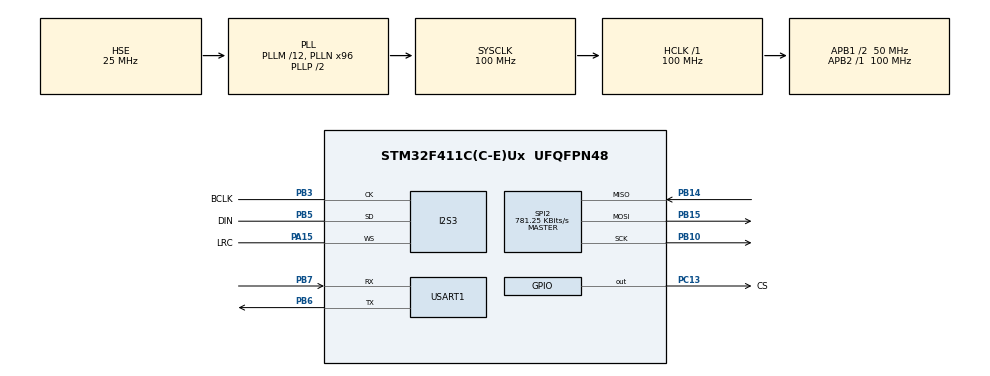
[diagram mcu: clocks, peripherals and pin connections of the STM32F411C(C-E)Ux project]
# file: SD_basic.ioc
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Dma.Request0=SPI2_RX
Dma.Request1=SPI2_TX
Dma.Request2=SPI3_TX
Dma.SPI2_RX.0.Direction=DMA_PERIPH_TO_MEMORY
Dma.SPI2_RX.0.FIFOMode=DMA_FIFOMODE_DISABLE
Dma.SPI2_RX.0.Instance=DMA1_Stream3
Dma.SPI2_RX.0.MemDataAlignment=DMA_MDATAALIGN_BYTE
Dma.SPI2_RX.0.MemInc=DMA_MINC_ENABLE
Dma.SPI2_RX.0.Mode=DMA_NORMAL
Dma.SPI2_RX.0.PeriphDataAlignment=DMA_PDATAALIGN_BYTE
Dma.SPI2_RX.0.PeriphInc=DMA_PINC_DISABLE
Dma.SPI2_RX.0.Priority=DMA_PRIORITY_LOW
Dma.SPI2_TX.1.Direction=DMA_MEMORY_TO_PERIPH
Dma.SPI2_TX.1.FIFOMode=DMA_FIFOMODE_DISABLE
Dma.SPI2_TX.1.Instance=DMA1_Stream4
Dma.SPI2_TX.1.MemDataAlignment=DMA_MDATAALIGN_BYTE
Dma.SPI2_TX.1.MemInc=DMA_MINC_ENABLE
Dma.SPI2_TX.1.Mode=DMA_NORMAL
Dma.SPI2_TX.1.PeriphDataAlignment=DMA_PDATAALIGN_BYTE
Dma.SPI2_TX.1.PeriphInc=DMA_PINC_DISABLE
Dma.SPI2_TX.1.Priority=DMA_PRIORITY_LOW
Dma.SPI3_TX.2.Direction=DMA_MEMORY_TO_PERIPH
Dma.SPI3_TX.2.FIFOMode=DMA_FIFOMODE_DISABLE
Dma.SPI3_TX.2.Instance=DMA1_Stream5
Dma.SPI3_TX.2.MemDataAlignment=DMA_MDATAALIGN_BYTE
Dma.SPI3_TX.2.MemInc=DMA_MINC_ENABLE
Dma.SPI3_TX.2.Mode=DMA_CIRCULAR
Dma.SPI3_TX.2.PeriphDataAlignment=DMA_PDATAALIGN_BYTE
Dma.SPI3_TX.2.PeriphInc=DMA_PINC_DISABLE
Dma.SPI3_TX.2.Priority=DMA_PRIORITY_LOW
FATFS._USE_LABEL=1
FATFS._USE_LFN=3
I2S3.AudioFreq=I2S_AUDIOFREQ_44K
I2S3.ErrorAudioFreq=-0.43 %
I2S3.FullDuplexMode=I2S_FULLDUPLEXMODE_DISABLE
I2S3.Instance=SPI$Index
I2S3.RealAudioFreq=43.808 KHz
I2S3.VirtualMode=I2S_MODE_MASTER
Mcu.Family=STM32F4
Mcu.Name=STM32F411C(C-E)Ux
Mcu.Package=UFQFPN48
NVIC.DMA1_Stream3_IRQn=true\:0\:0\:false\:false\:true\:false\:true\:true
NVIC.DMA1_Stream4_IRQn=true\:0\:0\:false\:false\:true\:false\:true\:true
NVIC.DMA1_Stream5_IRQn=true\:0\:0\:false\:false\:true\:false\:true\:true
NVIC.PriorityGroup=NVIC_PRIORITYGROUP_4
PA13.Mode=Serial_Wire
PA13.Signal=SYS_JTMS-SWDIO
PA14.Mode=Serial_Wire
PA14.Signal=SYS_JTCK-SWCLK
PA15.GPIO_Label=LRC
PA15.Mode=Half_Duplex_Master
PA15.Signal=I2S3_WS
PB10.Mode=Full_Duplex_Master
PB10.Signal=SPI2_SCK
PB14.Mode=Full_Duplex_Master
PB14.Signal=SPI2_MISO
PB15.Mode=Full_Duplex_Master
PB15.Signal=SPI2_MOSI
PB3.GPIO_Label=BCLK
PB3.Mode=Half_Duplex_Master
PB3.Signal=I2S3_CK
PB5.GPIO_Label=DIN
PB5.Mode=Half_Duplex_Master
PB5.Signal=I2S3_SD
PB6.Mode=Asynchronous
PB6.Signal=USART1_TX
PB7.Mode=Asynchronous
PB7.Signal=USART1_RX
PC13-ANTI_TAMP.GPIO_Label=CS
PC13-ANTI_TAMP.GPIO_Speed=GPIO_SPEED_FREQ_HIGH
PC13-ANTI_TAMP.PinState=GPIO_PIN_SET
PC13-ANTI_TAMP.Signal=GPIO_Output
PH0\ -\ OSC_IN.Mode=HSE-External-Oscillator
PH0\ -\ OSC_IN.Signal=RCC_OSC_IN
PH1\ -\ OSC_OUT.Mode=HSE-External-Oscillator
PH1\ -\ OSC_OUT.Signal=RCC_OSC_OUT
ProjectManager.HeapSize=0x200
ProjectManager.StackSize=0x400
ProjectManager.TargetToolchain=STM32CubeIDE
RCC.48MHZClocksFreq_Value=50000000
RCC.AHBFreq_Value=100000000
RCC.APB1CLKDivider=RCC_HCLK_DIV2
RCC.APB1Freq_Value=50000000
RCC.APB1TimFreq_Value=100000000
RCC.APB2Freq_Value=100000000
RCC.APB2TimFreq_Value=100000000
RCC.CortexFreq_Value=100000000
RCC.HCLKFreq_Value=100000000
RCC.HSE_VALUE=25000000
RCC.HSI_VALUE=16000000
RCC.LSE_VALUE=32768
RCC.PLLM=12
RCC.PLLN=96
RCC.PLLSourceVirtual=RCC_PLLSOURCE_HSE
RCC.SYSCLKFreq_VALUE=100000000
RCC.SYSCLKSource=RCC_SYSCLKSOURCE_PLLCLK
RCC.VCOOutputFreq_Value=200000000
SPI2.BaudRatePrescaler=SPI_BAUDRATEPRESCALER_64
SPI2.CalculateBaudRate=781.25 KBits/s
SPI2.Direction=SPI_DIRECTION_2LINES
SPI2.Mode=SPI_MODE_MASTER
SPI2.VirtualType=VM_MASTER
USART1.VirtualMode=VM_ASYNC
VP_FATFS_VS_Generic.Mode=User_defined
board=custom

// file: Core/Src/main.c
/* USER CODE BEGIN Header */
/**
  ******************************************************************************
  * @file           : main.c
  * @brief          : Main program body
  ******************************************************************************
  * @attention
  *
  * Copyright (c) 2026 STMicroelectronics.
  * All rights reserved.
  *
  * This software is licensed under terms that can be found in the LICENSE file
  * in the root directory of this software component.
  * If no LICENSE file comes with this software, it is provided AS-IS.
  *
  ******************************************************************************
  */
/* USER CODE END Header */
#include "main.h"
#include "fatfs.h"

/* USER CODE BEGIN Includes */
#include "sd_functions.h"
#include "stdio.h"
#include "sd_benchmark.h"
#include "wav_player.h"

/* USER CODE END Includes */

I2S_HandleTypeDef hi2s3;
DMA_HandleTypeDef hdma_spi3_tx;

SPI_HandleTypeDef hspi2;
DMA_HandleTypeDef hdma_spi2_rx;
DMA_HandleTypeDef hdma_spi2_tx;

UART_HandleTypeDef huart1;

void SystemClock_Config(void);
static void MX_GPIO_Init(void);
static void MX_DMA_Init(void);
static void MX_USART1_UART_Init(void);
static void MX_SPI2_Init(void);
static void MX_I2S3_Init(void);

/* USER CODE BEGIN 0 */
int _write(int fd, unsigned char *buf, int len) {
  if (fd == 1 || fd == 2) {                     // stdout or stderr ?
    HAL_UART_Transmit(&huart1, buf, len, 999);  // Print to the UART
  }
  return len;
}
/* USER CODE END 0 */

int main(void)
{

  /* MCU Configuration--------------------------------------------------------*/

  /* Reset of all peripherals, Initializes the Flash interface and the Systick. */
  HAL_Init();

  /* Configure the system clock */
  SystemClock_Config();

  /* Initialize all configured peripherals */
  MX_GPIO_Init();
  MX_DMA_Init();
  MX_USART1_UART_Init();
  MX_SPI2_Init();
  MX_I2S3_Init();
  /* USER CODE BEGIN 2 */
  sd_mount();
  sd_list_files();
  wav_set_volume(128);          /* 50% para começar */
  wav_play("bad_romance.wav");
  sd_unmount();
  /* USER CODE END 2 */

  /* Infinite loop */
  while (1)
  {

  }
}

void SystemClock_Config(void)
{
  RCC_OscInitTypeDef RCC_OscInitStruct = {0};
  RCC_ClkInitTypeDef RCC_ClkInitStruct = {0};

  /** Configure the main internal regulator output voltage
  */
  __HAL_RCC_PWR_CLK_ENABLE();
  __HAL_PWR_VOLTAGESCALING_CONFIG(PWR_REGULATOR_VOLTAGE_SCALE1);

  /** Initializes the RCC Oscillators according to the specified parameters
  * in the RCC_OscInitTypeDef structure.
  */
  RCC_OscInitStruct.OscillatorType = RCC_OSCILLATORTYPE_HSE;
  RCC_OscInitStruct.HSEState = RCC_HSE_ON;
  RCC_OscInitStruct.PLL.PLLState = RCC_PLL_ON;
  RCC_OscInitStruct.PLL.PLLSource = RCC_PLLSOURCE_HSE;
  RCC_OscInitStruct.PLL.PLLM = 12;
  RCC_OscInitStruct.PLL.PLLN = 96;
  RCC_OscInitStruct.PLL.PLLP = RCC_PLLP_DIV2;
  RCC_OscInitStruct.PLL.PLLQ = 4;
  if (HAL_RCC_OscConfig(&RCC_OscInitStruct) != HAL_OK)
  {
    Error_Handler();
  }

  /** Initializes the CPU, AHB and APB buses clocks
  */
  RCC_ClkInitStruct.ClockType = RCC_CLOCKTYPE_HCLK|RCC_CLOCKTYPE_SYSCLK
                              |RCC_CLOCKTYPE_PCLK1|RCC_CLOCKTYPE_PCLK2;
  RCC_ClkInitStruct.SYSCLKSource = RCC_SYSCLKSOURCE_PLLCLK;
  RCC_ClkInitStruct.AHBCLKDivider = RCC_SYSCLK_DIV1;
  RCC_ClkInitStruct.APB1CLKDivider = RCC_HCLK_DIV2;
  RCC_ClkInitStruct.APB2CLKDivider = RCC_HCLK_DIV1;

  if (HAL_RCC_ClockConfig(&RCC_ClkInitStruct, FLASH_LATENCY_3) != HAL_OK)
  {
    Error_Handler();
  }
}

static void MX_I2S3_Init(void)
{

  hi2s3.Instance = SPI3;
  hi2s3.Init.Mode = I2S_MODE_MASTER_TX;
  hi2s3.Init.Standard = I2S_STANDARD_PHILIPS;
  hi2s3.Init.DataFormat = I2S_DATAFORMAT_16B;
  hi2s3.Init.MCLKOutput = I2S_MCLKOUTPUT_DISABLE;
  hi2s3.Init.AudioFreq = I2S_AUDIOFREQ_44K;
  hi2s3.Init.CPOL = I2S_CPOL_LOW;
  hi2s3.Init.ClockSource = I2S_CLOCK_PLL;
  hi2s3.Init.FullDuplexMode = I2S_FULLDUPLEXMODE_DISABLE;
  if (HAL_I2S_Init(&hi2s3) != HAL_OK)
  {
    Error_Handler();
  }

}

static void MX_SPI2_Init(void)
{

  /* SPI2 parameter configuration*/
  hspi2.Instance = SPI2;
  hspi2.Init.Mode = SPI_MODE_MASTER;
  hspi2.Init.Direction = SPI_DIRECTION_2LINES;
  hspi2.Init.DataSize = SPI_DATASIZE_8BIT;
  hspi2.Init.CLKPolarity = SPI_POLARITY_LOW;
  hspi2.Init.CLKPhase = SPI_PHASE_1EDGE;
  hspi2.Init.NSS = SPI_NSS_SOFT;
  hspi2.Init.BaudRatePrescaler = SPI_BAUDRATEPRESCALER_32;
  hspi2.Init.FirstBit = SPI_FIRSTBIT_MSB;
  hspi2.Init.TIMode = SPI_TIMODE_DISABLE;
  hspi2.Init.CRCCalculation = SPI_CRCCALCULATION_DISABLE;
  hspi2.Init.CRCPolynomial = 10;
  if (HAL_SPI_Init(&hspi2) != HAL_OK)
  {
    Error_Handler();
  }

}

static void MX_USART1_UART_Init(void)
{

  huart1.Instance = USART1;
  huart1.Init.BaudRate = 115200;
  huart1.Init.WordLength = UART_WORDLENGTH_8B;
  huart1.Init.StopBits = UART_STOPBITS_1;
  huart1.Init.Parity = UART_PARITY_NONE;
  huart1.Init.Mode = UART_MODE_TX_RX;
  huart1.Init.HwFlowCtl = UART_HWCONTROL_NONE;
  huart1.Init.OverSampling = UART_OVERSAMPLING_16;
  if (HAL_UART_Init(&huart1) != HAL_OK)
  {
    Error_Handler();
  }

}

static void MX_DMA_Init(void)
{

  /* DMA controller clock enable */
  __HAL_RCC_DMA1_CLK_ENABLE();

  /* DMA interrupt init */
  /* DMA1_Stream3_IRQn interrupt configuration */
  HAL_NVIC_SetPriority(DMA1_Stream3_IRQn, 0, 0);
  HAL_NVIC_EnableIRQ(DMA1_Stream3_IRQn);
  /* DMA1_Stream4_IRQn interrupt configuration */
  HAL_NVIC_SetPriority(DMA1_Stream4_IRQn, 0, 0);
  HAL_NVIC_EnableIRQ(DMA1_Stream4_IRQn);
  /* DMA1_Stream5_IRQn interrupt configuration */
  HAL_NVIC_SetPriority(DMA1_Stream5_IRQn, 0, 0);
  HAL_NVIC_EnableIRQ(DMA1_Stream5_IRQn);

}

static void MX_GPIO_Init(void)
{
  GPIO_InitTypeDef GPIO_InitStruct = {0};

  /* GPIO Ports Clock Enable */
  __HAL_RCC_GPIOC_CLK_ENABLE();
  __HAL_RCC_GPIOH_CLK_ENABLE();
  __HAL_RCC_GPIOB_CLK_ENABLE();
  __HAL_RCC_GPIOA_CLK_ENABLE();

  /*Configure GPIO pin Output Level */
  HAL_GPIO_WritePin(CS_GPIO_Port, CS_Pin, GPIO_PIN_SET);

  /*Configure GPIO pin : CS_Pin */
  GPIO_InitStruct.Pin = CS_Pin;
  GPIO_InitStruct.Mode = GPIO_MODE_OUTPUT_PP;
  GPIO_InitStruct.Pull = GPIO_NOPULL;
  GPIO_InitStruct.Speed = GPIO_SPEED_FREQ_HIGH;
  HAL_GPIO_Init(CS_GPIO_Port, &GPIO_InitStruct);

}

void Error_Handler(void)
{
  __disable_irq();
  while (1)
  {
  }
}
